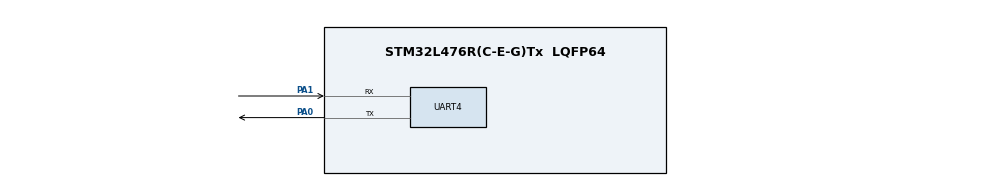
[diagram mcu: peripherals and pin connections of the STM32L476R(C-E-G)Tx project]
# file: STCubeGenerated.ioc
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Mcu.Family=STM32L4
Mcu.Name=STM32L476R(C-E-G)Tx
Mcu.Package=LQFP64
NVIC.PriorityGroup=NVIC_PRIORITYGROUP_4
PA0.Mode=Asynchronous
PA0.Signal=UART4_TX
PA1.Mode=Asynchronous
PA1.Signal=UART4_RX
PA13\ (JTMS-SWDIO).Mode=Serial_Wire
PA13\ (JTMS-SWDIO).Signal=SYS_JTMS-SWDIO
PA14\ (JTCK-SWCLK).Mode=Serial_Wire
PA14\ (JTCK-SWCLK).Signal=SYS_JTCK-SWCLK
ProjectManager.HeapSize=0x200
ProjectManager.StackSize=0x400
ProjectManager.TargetToolchain=Makefile
RCC.HSE_VALUE=8000000
RCC.HSI_VALUE=16000000
RCC.LSE_VALUE=32768
RCC.MSI_VALUE=4000000
RCC.VCOOutputFreq_Value=32000000
UART4.WordLength=WORDLENGTH_8B
board=STCubeGenerated

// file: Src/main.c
/**
  ******************************************************************************
  * File Name          : main.c
  * Description        : Main program body
  ******************************************************************************
  ** This notice applies to any and all portions of this file
  * that are not between comment pairs USER CODE BEGIN and
  * USER CODE END. Other portions of this file, whether
  * inserted by the user or by software development tools
  * are owned by their respective copyright owners.
  *
  * COPYRIGHT(c) 2018 STMicroelectronics
  *
  * Redistribution and use in source and binary forms, with or without modification,
  * are permitted provided that the following conditions are met:
  *   1. Redistributions of source code must retain the above copyright notice,
  *      this list of conditions and the following disclaimer.
  *   2. Redistributions in binary form must reproduce the above copyright notice,
  *      this list of conditions and the following disclaimer in the documentation
  *      and/or other materials provided with the distribution.
  *   3. Neither the name of STMicroelectronics nor the names of its contributors
  *      may be used to endorse or promote products derived from this software
  *      without specific prior written permission.
  *
  * THIS SOFTWARE IS PROVIDED BY THE COPYRIGHT HOLDERS AND CONTRIBUTORS "AS IS"
  * AND ANY EXPRESS OR IMPLIED WARRANTIES, INCLUDING, BUT NOT LIMITED TO, THE
  * IMPLIED WARRANTIES OF MERCHANTABILITY AND FITNESS FOR A PARTICULAR PURPOSE ARE
  * DISCLAIMED. IN NO EVENT SHALL THE COPYRIGHT HOLDER OR CONTRIBUTORS BE LIABLE
  * FOR ANY DIRECT, INDIRECT, INCIDENTAL, SPECIAL, EXEMPLARY, OR CONSEQUENTIAL
  * DAMAGES (INCLUDING, BUT NOT LIMITED TO, PROCUREMENT OF SUBSTITUTE GOODS OR
  * SERVICES; LOSS OF USE, DATA, OR PROFITS; OR BUSINESS INTERRUPTION) HOWEVER
  * CAUSED AND ON ANY THEORY OF LIABILITY, WHETHER IN CONTRACT, STRICT LIABILITY,
  * OR TORT (INCLUDING NEGLIGENCE OR OTHERWISE) ARISING IN ANY WAY OUT OF THE USE
  * OF THIS SOFTWARE, EVEN IF ADVISED OF THE POSSIBILITY OF SUCH DAMAGE.
  *
  ******************************************************************************
  */

#include "main.h"
#include "stm32l4xx_hal.h"

/* USER CODE BEGIN Includes */
#include <string.h>
/* USER CODE END Includes */

UART_HandleTypeDef huart4;

/* USER CODE BEGIN PV */
/* Private variables ---------------------------------------------------------*/
HAL_StatusTypeDef returnValue;
/* Buffer used for transmission */
uint8_t aTxBuffer[] =  "Hello World";

/* Buffer used for reception */
uint8_t aRxBuffer[15];
/* USER CODE END PV */

void SystemClock_Config(void);
static void MX_GPIO_Init(void);
static void MX_UART4_Init(void);

/* USER CODE BEGIN PFP */
/* Private function prototypes -----------------------------------------------*/

/* USER CODE END PFP */

/* USER CODE BEGIN 0 */
int printWelcomeMessage(void);
int echoFun(void);
/* USER CODE END 0 */

int main(void)
{

  /* MCU Configuration----------------------------------------------------------*/

  /* Reset of all peripherals, Initializes the Flash interface and the Systick. */
  HAL_Init();

  /* Configure the system clock */
  SystemClock_Config();

  /* Initialize all configured peripherals */
  MX_GPIO_Init();
  MX_UART4_Init();

  /* Infinite loop */
  /* USER CODE BEGIN WHILE */
	printWelcomeMessage();
	  while (1)
  {
  /* USER CODE END WHILE */

  /* USER CODE BEGIN 3 */
		printWelcomeMessage();
		echoFun();
  }
  /* USER CODE END 3 */

}

/** System Clock Configuration
*/
void SystemClock_Config(void)
{

  RCC_OscInitTypeDef RCC_OscInitStruct;
  RCC_ClkInitTypeDef RCC_ClkInitStruct;
  RCC_PeriphCLKInitTypeDef PeriphClkInit;

    /**Initializes the CPU, AHB and APB busses clocks
    */
  RCC_OscInitStruct.OscillatorType = RCC_OSCILLATORTYPE_MSI;
  RCC_OscInitStruct.MSIState = RCC_MSI_ON;
  RCC_OscInitStruct.MSICalibrationValue = 0;
  RCC_OscInitStruct.MSIClockRange = RCC_MSIRANGE_6;
  RCC_OscInitStruct.PLL.PLLState = RCC_PLL_NONE;
  if (HAL_RCC_OscConfig(&RCC_OscInitStruct) != HAL_OK)
  {
    _Error_Handler(__FILE__, __LINE__);
  }

    /**Initializes the CPU, AHB and APB busses clocks
    */
  RCC_ClkInitStruct.ClockType = RCC_CLOCKTYPE_HCLK|RCC_CLOCKTYPE_SYSCLK
                              |RCC_CLOCKTYPE_PCLK1|RCC_CLOCKTYPE_PCLK2;
  RCC_ClkInitStruct.SYSCLKSource = RCC_SYSCLKSOURCE_MSI;
  RCC_ClkInitStruct.AHBCLKDivider = RCC_SYSCLK_DIV1;
  RCC_ClkInitStruct.APB1CLKDivider = RCC_HCLK_DIV1;
  RCC_ClkInitStruct.APB2CLKDivider = RCC_HCLK_DIV1;

  if (HAL_RCC_ClockConfig(&RCC_ClkInitStruct, FLASH_LATENCY_0) != HAL_OK)
  {
    _Error_Handler(__FILE__, __LINE__);
  }

  PeriphClkInit.PeriphClockSelection = RCC_PERIPHCLK_UART4;
  PeriphClkInit.Uart4ClockSelection = RCC_UART4CLKSOURCE_PCLK1;
  if (HAL_RCCEx_PeriphCLKConfig(&PeriphClkInit) != HAL_OK)
  {
    _Error_Handler(__FILE__, __LINE__);
  }

    /**Configure the main internal regulator output voltage
    */
  if (HAL_PWREx_ControlVoltageScaling(PWR_REGULATOR_VOLTAGE_SCALE1) != HAL_OK)
  {
    _Error_Handler(__FILE__, __LINE__);
  }

    /**Configure the Systick interrupt time
    */
  HAL_SYSTICK_Config(HAL_RCC_GetHCLKFreq()/1000);

    /**Configure the Systick
    */
  HAL_SYSTICK_CLKSourceConfig(SYSTICK_CLKSOURCE_HCLK);

  /* SysTick_IRQn interrupt configuration */
  HAL_NVIC_SetPriority(SysTick_IRQn, 0, 0);
}

/* UART4 init function */
static void MX_UART4_Init(void)
{

  huart4.Instance = UART4;
  huart4.Init.BaudRate = 115200;
  huart4.Init.WordLength = UART_WORDLENGTH_8B;
  huart4.Init.StopBits = UART_STOPBITS_1;
  huart4.Init.Parity = UART_PARITY_NONE;
  huart4.Init.Mode = UART_MODE_TX_RX;
  huart4.Init.HwFlowCtl = UART_HWCONTROL_NONE;
  huart4.Init.OverSampling = UART_OVERSAMPLING_16;
  huart4.Init.OneBitSampling = UART_ONE_BIT_SAMPLE_DISABLE;
  huart4.AdvancedInit.AdvFeatureInit = UART_ADVFEATURE_NO_INIT;
  if (HAL_UART_Init(&huart4) != HAL_OK)
  {
    _Error_Handler(__FILE__, __LINE__);
  }

}

/** Configure pins as
        * Analog
        * Input
        * Output
        * EVENT_OUT
        * EXTI
*/
static void MX_GPIO_Init(void)
{

  /* GPIO Ports Clock Enable */
  __HAL_RCC_GPIOA_CLK_ENABLE();

}

/* USER CODE BEGIN 4 */
int printWelcomeMessage(void){
	returnValue = HAL_UART_Transmit(&huart4,(uint8_t*)"Hello World",strlen("Hello World"),100);
	if (returnValue != HAL_OK) {
		return 0;
	}
	return 1;
}

int echoFun(void){

	returnValue = HAL_UART_Receive(&huart4, (uint8_t *)aRxBuffer, strlen("Hello World"), 5000);
	if (returnValue != HAL_OK) {
		return 0;
	}
	else{
		HAL_UART_Transmit(&huart4,(uint8_t*)"hola guapeton",strlen("hola guapeton"),100);
	}
	return 1;
}
/* USER CODE END 4 */

void _Error_Handler(char * file, int line)
{
  while(1)
  {
  }
}

/************************ (C) COPYRIGHT STMicroelectronics *****END OF FILE****/
